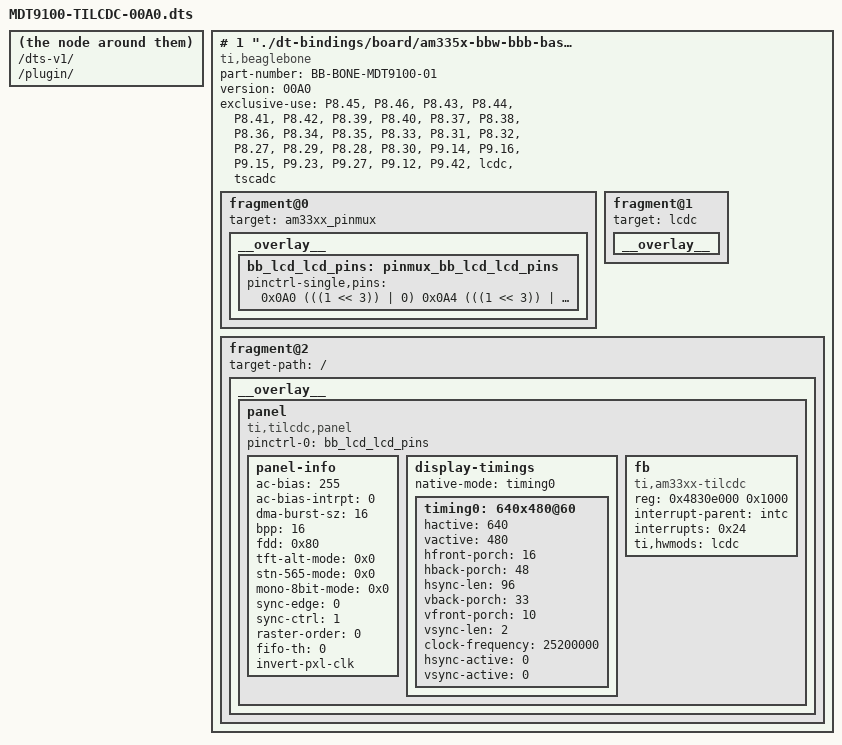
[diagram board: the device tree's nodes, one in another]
# 1 "gold.dts"
# 1 "<built-in>"
# 1 "<command-line>"
# 1 "gold.dts"







/dts-v1/;
/plugin/;

# 1 "./dt-bindings/board/am335x-bbw-bbb-base.h" 1
# 12 "gold.dts" 2
# 1 "./dt-bindings/gpio/gpio.h" 1
# 13 "gold.dts" 2
# 1 "./dt-bindings/pinctrl/am33xx.h" 1







# 1 "./dt-bindings/pinctrl/omap.h" 1
# 9 "./dt-bindings/pinctrl/am33xx.h" 2
# 14 "gold.dts" 2

/ {
 compatible = "ti,beaglebone", "ti,beaglebone-black", "ti,beaglebone-green";


 part-number = "BB-BONE-MDT9100-01";
 version = "00A0";


 exclusive-use =

  "P8.45",
  "P8.46",
  "P8.43",
  "P8.44",
  "P8.41",
  "P8.42",
  "P8.39",
  "P8.40",
  "P8.37",
  "P8.38",
  "P8.36",
  "P8.34",
  "P8.35",
  "P8.33",
  "P8.31",
  "P8.32",
  "P8.27",
  "P8.29",
  "P8.28",
  "P8.30",
  "P9.14",
  "P9.16",
  "P9.15",
  "P9.23",
  "P9.27",
  "P9.12",
  "P9.42",

  "lcdc",
  "tscadc";

 fragment@0 {
  target = <&am33xx_pinmux>;
  __overlay__ {

   bb_lcd_lcd_pins: pinmux_bb_lcd_lcd_pins {
    pinctrl-single,pins = <
     0x0A0 (((1 << 3)) | 0)
     0x0A4 (((1 << 3)) | 0)
     0x0A8 (((1 << 3)) | 0)
     0x0AC (((1 << 3)) | 0)
     0x0B0 (((1 << 3)) | 0)
     0x0B4 (((1 << 3)) | 0)
     0x0B8 (((1 << 3)) | 0)
     0x0BC (((1 << 3)) | 0)
     0x0C0 (((1 << 3)) | 0)
     0x0C4 (((1 << 3)) | 0)
     0x0C8 (((1 << 3)) | 0)
     0x0CC (((1 << 3)) | 0)
     0x0D0 (((1 << 3)) | 0)
     0x0D4 (((1 << 3)) | 0)
     0x0D8 (((1 << 3)) | 0)
     0x0DC (((1 << 3)) | 0)

     0x0E0 (((1 << 3)) | 0)
     0x0E4 (((1 << 3)) | 0)
     0x0E8 (((1 << 3)) | 0)
     0x0EC (((1 << 3)) | 0)
    >;
   };
  };
 };

 fragment@1 {
  target = <&lcdc>;
  __overlay__ {
   status = "okay";
  };
 };


 fragment@2 {
  target-path="/";
  __overlay__ {


   #address-cells = <1>;
   #size-cells = <1>;


   panel {
    status = "okay";
    compatible = "ti,tilcdc,panel";
    pinctrl-names = "default";
    pinctrl-0 = <&bb_lcd_lcd_pins>;
    panel-info {
     ac-bias = <255>;
     ac-bias-intrpt = <0>;
     dma-burst-sz = <16>;
     bpp = <16>;
     fdd = <0x80>;
     tft-alt-mode = <0x0>;
     stn-565-mode = <0x0>;
     mono-8bit-mode = <0x0>;
     sync-edge = <0>;
     sync-ctrl = <1>;
     raster-order = <0>;
     fifo-th = <0>;
     invert-pxl-clk;
    };
    display-timings {
     native-mode = <&timing0>;

     timing0: 640x480@60 {
      hactive = <640>;
      vactive = <480>;
      hfront-porch = <16>;
      hback-porch = <48>;
      hsync-len = <96>;
      vback-porch = <33>;
      vfront-porch = <10>;
      vsync-len = <2>;
      clock-frequency = <25200000>;
      hsync-active = <0>;
      vsync-active = <0>;
     };
    };
    fb {
     compatible = "ti,am33xx-tilcdc";
     reg = <0x4830e000 0x1000>;
     interrupt-parent = <&intc>;
     interrupts = <0x24>;
     ti,hwmods = "lcdc";
    };
   };
  };
 };
};
